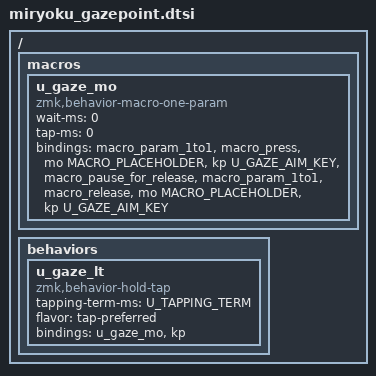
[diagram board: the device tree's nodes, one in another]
// gazepoint integration: see miryoku_gazepoint.h.

/ {
  macros {
    // &mo LAYER plus holding the aim key, for as long as the binding is held.
    u_gaze_mo: u_gaze_mo {
      compatible = "zmk,behavior-macro-one-param";
      #binding-cells = <1>;
      wait-ms = <0>;
      tap-ms = <0>;
      bindings
        = <&macro_param_1to1>
        , <&macro_press &mo MACRO_PLACEHOLDER &kp U_GAZE_AIM_KEY>
        , <&macro_pause_for_release>
        , <&macro_param_1to1>
        , <&macro_release &mo MACRO_PLACEHOLDER &kp U_GAZE_AIM_KEY>
        ;
    };
  };
  behaviors {
    // Like u_lt, but the hold also aims gazepoint.
    u_gaze_lt: u_gaze_lt {
      compatible = "zmk,behavior-hold-tap";
      #binding-cells = <2>;
      tapping-term-ms = <U_TAPPING_TERM>;
      flavor = "tap-preferred";
      bindings = <&u_gaze_mo>, <&kp>;
    };
  };
};
